# EFM32JG12B500F1024GL125 register map
File version: 4.0.0
CPU: CM3 r2p1, little endian, MPU, no FPU, 3 interrupt priority bits
Registers are 32-bit, read-write, reset 0x0 unless marked. A register's access mark holds for its fields unless they carry their own. Offsets are from the block's base; [hi:lo] are bit positions; lines under a group give offsets from that group; {n}, {i} and the like mark numbered series; 'fields as' and 'values as' point back to an identical list.

## GPIO
Base 0x4000A000
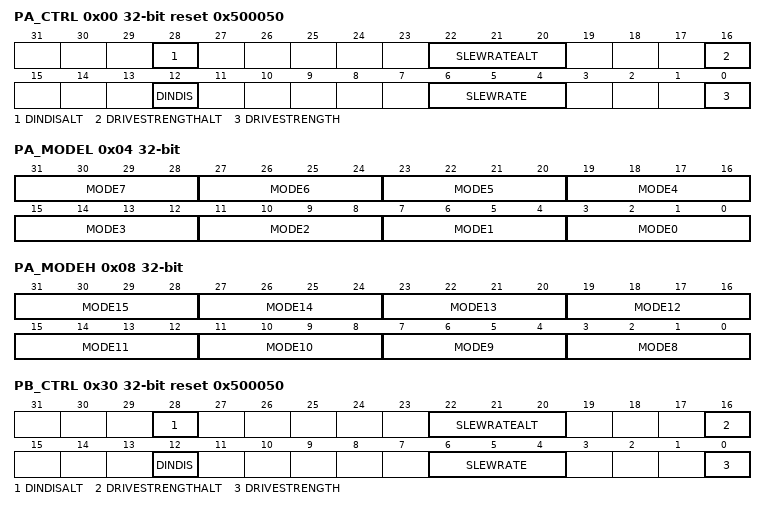
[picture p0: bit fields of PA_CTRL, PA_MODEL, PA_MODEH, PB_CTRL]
0x00 PA_CTRL reset 0x500050 — Port Control Register
  [28] DINDISALT — Alternate Data in Disable
  [22:20] SLEWRATEALT — Alternate Slewrate Limit for Port
  [16] DRIVESTRENGTHALT — Alternate Drive Strength for Port
  [12] DINDIS — Data in Disable
  [6:4] SLEWRATE — Slewrate Limit for Port
  [0] DRIVESTRENGTH — Drive Strength for Port
0x04 PA_MODEL — Port Pin Mode Low Register
  [all] fields
    0=DISABLED (Input disabled. Pullup if DOUT is set.); 1=INPUT (Input enabled. Filter if DOUT is set); 2=INPUTPULL (Input enabled. DOUT determines pull direction); 3=INPUTPULLFILTER (Input enabled with filter. DOUT determines pull direction); 4=PUSHPULL (Push-pull output); 5=PUSHPULLALT (Push-pull using alternate control); 6=WIREDOR (Wired-or output); 7=WIREDORPULLDOWN (Wired-or output with pull-down); 8=WIREDAND (Open-drain output); 9=WIREDANDFILTER (Open-drain output with filter); 10=WIREDANDPULLUP (Open-drain output with pullup); 11=WIREDANDPULLUPFILTER (Open-drain output with filter and pullup); 12=WIREDANDALT (Open-drain output using alternate control); 13=WIREDANDALTFILTER (Open-drain output using alternate control with filter); 14=WIREDANDALTPULLUP (Open-drain output using alternate control with pullup); 15=WIREDANDALTPULLUPFILTER (Open-drain output using alternate control with filter and pullup)
  [4n+3:4n] MODE{n} (n=0..7) — Pin {n} Mode
0x08 PA_MODEH — Port Pin Mode High Register
  [all] fields
    values as the fields of PA_MODEL
  [4n-29:4n-32] MODE{n} (n=8..15) — Pin {n} Mode
0x0C PA_DOUT — Port Data Out Register
  [15:0] DOUT — Data Out
0x18 PA_DOUTTGL wo — Port Data Out Toggle Register
  [15:0] DOUTTGL — Data Out Toggle
0x1C PA_DIN ro — Port Data in Register
  [15:0] DIN — Data in
0x20 PA_PINLOCKN reset 0xFFFF — Port Unlocked Pins Register
  [15:0] PINLOCKN — Unlocked Pins
0x28 PA_OVTDIS — Over Voltage Disable for All Modes
  [15:0] OVTDIS — Disable Over Voltage Capability
0x30 PB_CTRL reset 0x500050 — Port Control Register
  fields as PA_CTRL
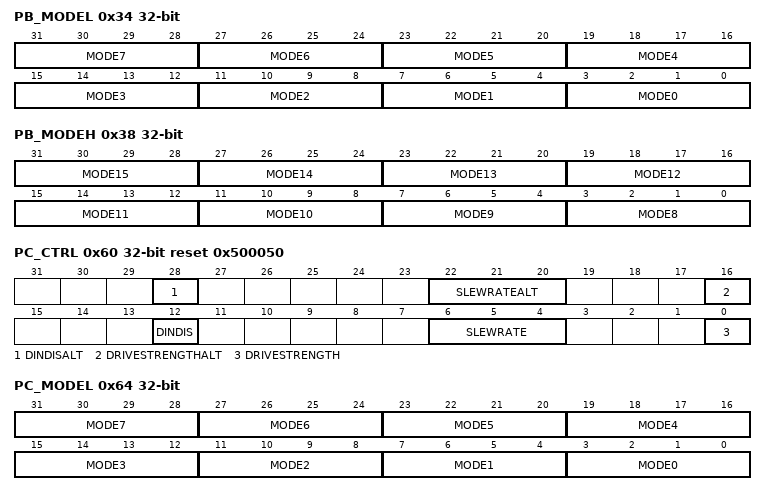
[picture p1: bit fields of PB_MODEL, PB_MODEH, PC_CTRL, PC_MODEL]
0x34 PB_MODEL — Port Pin Mode Low Register
  fields as PA_MODEL
0x38 PB_MODEH — Port Pin Mode High Register
  fields as PA_MODEH
0x3C PB_DOUT — Port Data Out Register
  [15:0] DOUT — Data Out
0x48 PB_DOUTTGL wo — Port Data Out Toggle Register
  [15:0] DOUTTGL — Data Out Toggle
0x4C PB_DIN ro — Port Data in Register
  [15:0] DIN — Data in
0x50 PB_PINLOCKN reset 0xFFFF — Port Unlocked Pins Register
  [15:0] PINLOCKN — Unlocked Pins
0x58 PB_OVTDIS — Over Voltage Disable for All Modes
  [15:0] OVTDIS — Disable Over Voltage Capability
0x60 PC_CTRL reset 0x500050 — Port Control Register
  fields as PA_CTRL
0x64 PC_MODEL — Port Pin Mode Low Register
  fields as PA_MODEL
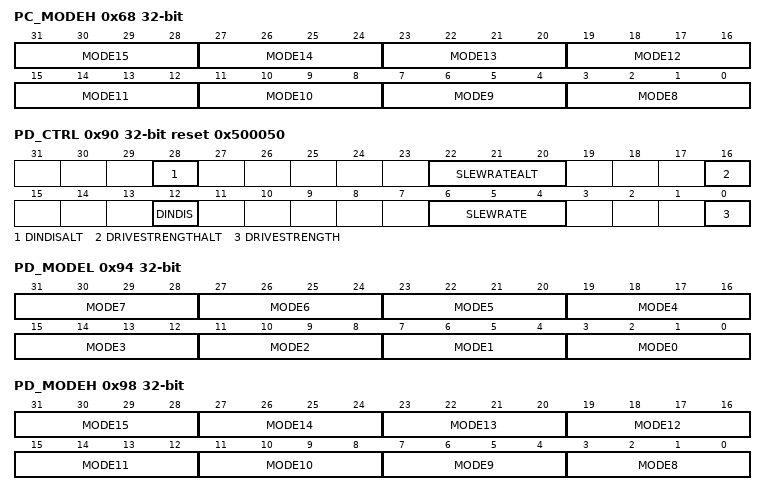
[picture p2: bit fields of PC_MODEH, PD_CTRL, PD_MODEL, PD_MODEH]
0x68 PC_MODEH — Port Pin Mode High Register
  fields as PA_MODEH
0x6C PC_DOUT — Port Data Out Register
  [15:0] DOUT — Data Out
0x78 PC_DOUTTGL wo — Port Data Out Toggle Register
  [15:0] DOUTTGL — Data Out Toggle
0x7C PC_DIN ro — Port Data in Register
  [15:0] DIN — Data in
0x80 PC_PINLOCKN reset 0xFFFF — Port Unlocked Pins Register
  [15:0] PINLOCKN — Unlocked Pins
0x88 PC_OVTDIS — Over Voltage Disable for All Modes
  [15:0] OVTDIS — Disable Over Voltage Capability
0x90 PD_CTRL reset 0x500050 — Port Control Register
  fields as PA_CTRL
0x94 PD_MODEL — Port Pin Mode Low Register
  fields as PA_MODEL
0x98 PD_MODEH — Port Pin Mode High Register
  fields as PA_MODEH
0x9C PD_DOUT — Port Data Out Register
  [15:0] DOUT — Data Out
0xA8 PD_DOUTTGL wo — Port Data Out Toggle Register
  [15:0] DOUTTGL — Data Out Toggle
0xAC PD_DIN ro — Port Data in Register
  [15:0] DIN — Data in
0xB0 PD_PINLOCKN reset 0xFFFF — Port Unlocked Pins Register
  [15:0] PINLOCKN — Unlocked Pins
0xB8 PD_OVTDIS — Over Voltage Disable for All Modes
  [15:0] OVTDIS — Disable Over Voltage Capability
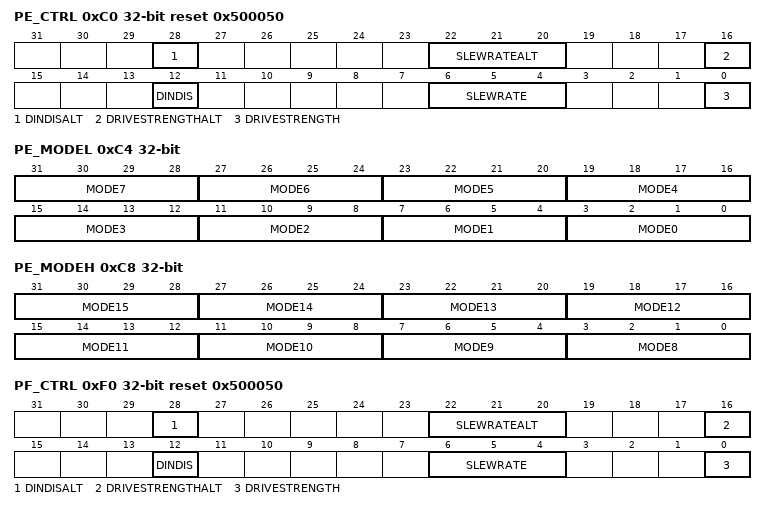
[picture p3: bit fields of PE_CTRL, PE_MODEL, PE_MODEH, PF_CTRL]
0xC0 PE_CTRL reset 0x500050 — Port Control Register
  fields as PA_CTRL
0xC4 PE_MODEL — Port Pin Mode Low Register
  fields as PA_MODEL
0xC8 PE_MODEH — Port Pin Mode High Register
  fields as PA_MODEH
0xCC PE_DOUT — Port Data Out Register
  [15:0] DOUT — Data Out
0xD8 PE_DOUTTGL wo — Port Data Out Toggle Register
  [15:0] DOUTTGL — Data Out Toggle
0xDC PE_DIN ro — Port Data in Register
  [15:0] DIN — Data in
0xE0 PE_PINLOCKN reset 0xFFFF — Port Unlocked Pins Register
  [15:0] PINLOCKN — Unlocked Pins
0xE8 PE_OVTDIS — Over Voltage Disable for All Modes
  [15:0] OVTDIS — Disable Over Voltage Capability
0xF0 PF_CTRL reset 0x500050 — Port Control Register
  fields as PA_CTRL
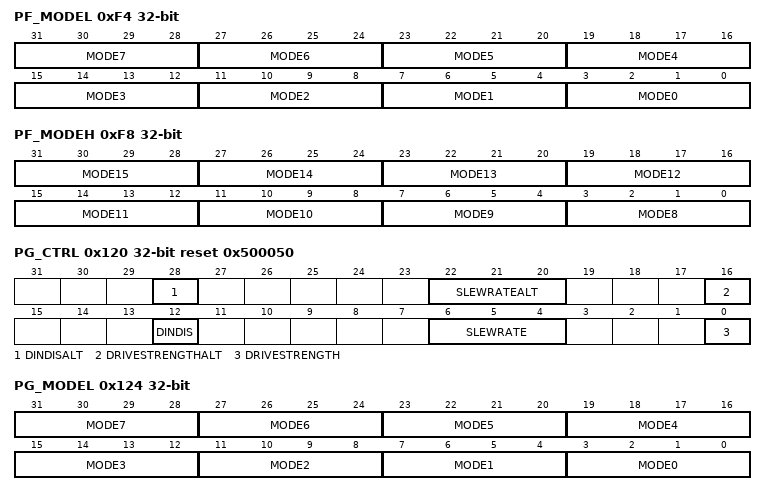
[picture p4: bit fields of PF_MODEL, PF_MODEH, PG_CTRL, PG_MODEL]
0xF4 PF_MODEL — Port Pin Mode Low Register
  fields as PA_MODEL
0xF8 PF_MODEH — Port Pin Mode High Register
  fields as PA_MODEH
0xFC PF_DOUT — Port Data Out Register
  [15:0] DOUT — Data Out
0x108 PF_DOUTTGL wo — Port Data Out Toggle Register
  [15:0] DOUTTGL — Data Out Toggle
0x10C PF_DIN ro — Port Data in Register
  [15:0] DIN — Data in
0x110 PF_PINLOCKN reset 0xFFFF — Port Unlocked Pins Register
  [15:0] PINLOCKN — Unlocked Pins
0x118 PF_OVTDIS — Over Voltage Disable for All Modes
  [15:0] OVTDIS — Disable Over Voltage Capability
0x120 PG_CTRL reset 0x500050 — Port Control Register
  fields as PA_CTRL
0x124 PG_MODEL — Port Pin Mode Low Register
  fields as PA_MODEL
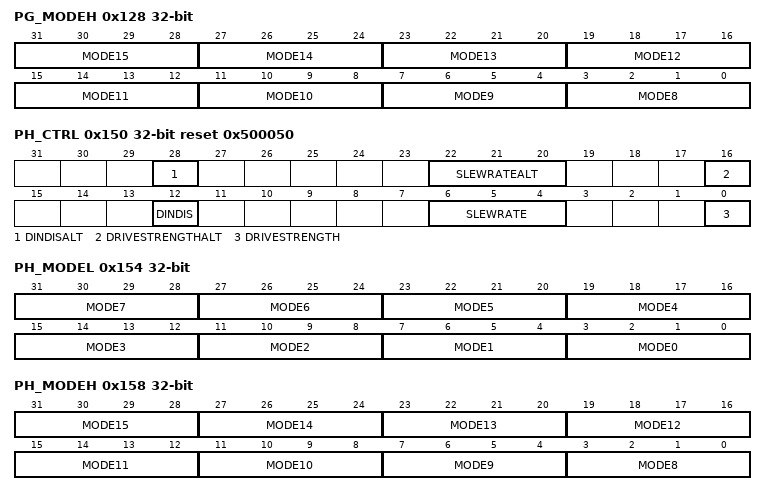
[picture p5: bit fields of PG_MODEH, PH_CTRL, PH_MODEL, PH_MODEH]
0x128 PG_MODEH — Port Pin Mode High Register
  fields as PA_MODEH
0x12C PG_DOUT — Port Data Out Register
  [15:0] DOUT — Data Out
0x138 PG_DOUTTGL wo — Port Data Out Toggle Register
  [15:0] DOUTTGL — Data Out Toggle
0x13C PG_DIN ro — Port Data in Register
  [15:0] DIN — Data in
0x140 PG_PINLOCKN reset 0xFFFF — Port Unlocked Pins Register
  [15:0] PINLOCKN — Unlocked Pins
0x148 PG_OVTDIS — Over Voltage Disable for All Modes
  [15:0] OVTDIS — Disable Over Voltage Capability
0x150 PH_CTRL reset 0x500050 — Port Control Register
  fields as PA_CTRL
0x154 PH_MODEL — Port Pin Mode Low Register
  fields as PA_MODEL
0x158 PH_MODEH — Port Pin Mode High Register
  fields as PA_MODEH
0x15C PH_DOUT — Port Data Out Register
  [15:0] DOUT — Data Out
0x168 PH_DOUTTGL wo — Port Data Out Toggle Register
  [15:0] DOUTTGL — Data Out Toggle
0x16C PH_DIN ro — Port Data in Register
  [15:0] DIN — Data in
0x170 PH_PINLOCKN reset 0xFFFF — Port Unlocked Pins Register
  [15:0] PINLOCKN — Unlocked Pins
0x178 PH_OVTDIS — Over Voltage Disable for All Modes
  [15:0] OVTDIS — Disable Over Voltage Capability
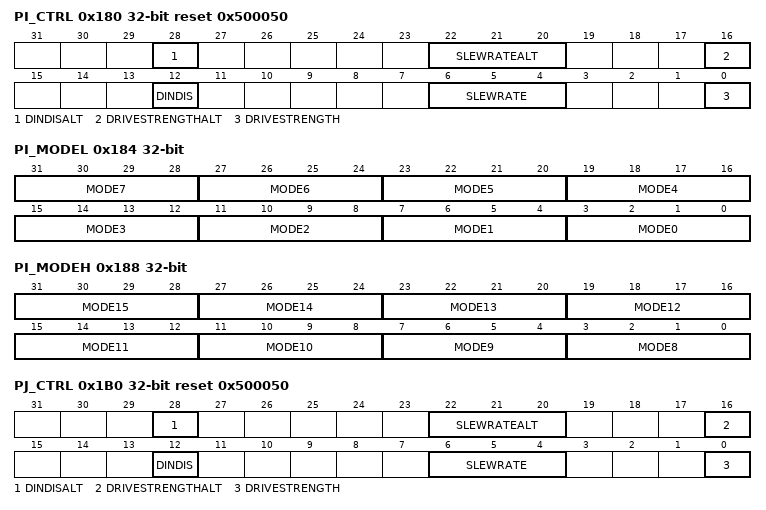
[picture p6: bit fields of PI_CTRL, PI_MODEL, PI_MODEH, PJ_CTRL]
0x180 PI_CTRL reset 0x500050 — Port Control Register
  fields as PA_CTRL
0x184 PI_MODEL — Port Pin Mode Low Register
  fields as PA_MODEL
0x188 PI_MODEH — Port Pin Mode High Register
  fields as PA_MODEH
0x18C PI_DOUT — Port Data Out Register
  [15:0] DOUT — Data Out
0x198 PI_DOUTTGL wo — Port Data Out Toggle Register
  [15:0] DOUTTGL — Data Out Toggle
0x19C PI_DIN ro — Port Data in Register
  [15:0] DIN — Data in
0x1A0 PI_PINLOCKN reset 0xFFFF — Port Unlocked Pins Register
  [15:0] PINLOCKN — Unlocked Pins
0x1A8 PI_OVTDIS — Over Voltage Disable for All Modes
  [15:0] OVTDIS — Disable Over Voltage Capability
0x1B0 PJ_CTRL reset 0x500050 — Port Control Register
  fields as PA_CTRL
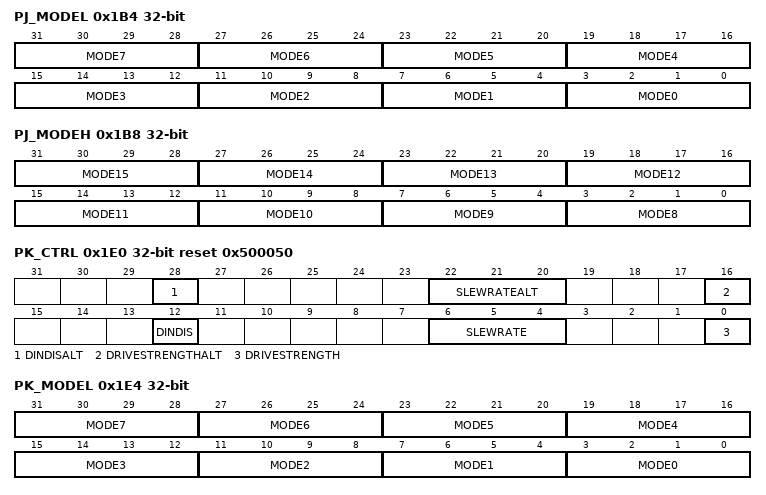
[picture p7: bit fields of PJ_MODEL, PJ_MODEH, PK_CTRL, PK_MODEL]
0x1B4 PJ_MODEL — Port Pin Mode Low Register
  fields as PA_MODEL
0x1B8 PJ_MODEH — Port Pin Mode High Register
  fields as PA_MODEH
0x1BC PJ_DOUT — Port Data Out Register
  [15:0] DOUT — Data Out
0x1C8 PJ_DOUTTGL wo — Port Data Out Toggle Register
  [15:0] DOUTTGL — Data Out Toggle
0x1CC PJ_DIN ro — Port Data in Register
  [15:0] DIN — Data in
0x1D0 PJ_PINLOCKN reset 0xFFFF — Port Unlocked Pins Register
  [15:0] PINLOCKN — Unlocked Pins
0x1D8 PJ_OVTDIS — Over Voltage Disable for All Modes
  [15:0] OVTDIS — Disable Over Voltage Capability
0x1E0 PK_CTRL reset 0x500050 — Port Control Register
  fields as PA_CTRL
0x1E4 PK_MODEL — Port Pin Mode Low Register
  fields as PA_MODEL
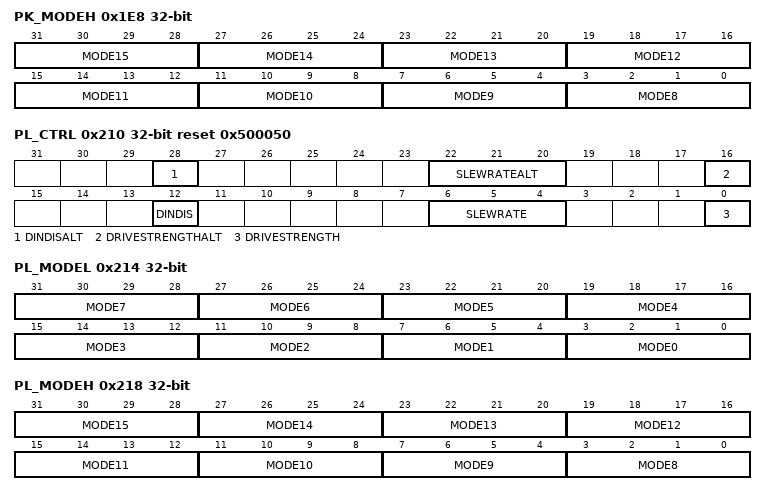
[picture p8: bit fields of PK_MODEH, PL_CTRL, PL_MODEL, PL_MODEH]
0x1E8 PK_MODEH — Port Pin Mode High Register
  fields as PA_MODEH
0x1EC PK_DOUT — Port Data Out Register
  [15:0] DOUT — Data Out
0x1F8 PK_DOUTTGL wo — Port Data Out Toggle Register
  [15:0] DOUTTGL — Data Out Toggle
0x1FC PK_DIN ro — Port Data in Register
  [15:0] DIN — Data in
0x200 PK_PINLOCKN reset 0xFFFF — Port Unlocked Pins Register
  [15:0] PINLOCKN — Unlocked Pins
0x208 PK_OVTDIS — Over Voltage Disable for All Modes
  [15:0] OVTDIS — Disable Over Voltage Capability
0x210 PL_CTRL reset 0x500050 — Port Control Register
  fields as PA_CTRL
0x214 PL_MODEL — Port Pin Mode Low Register
  fields as PA_MODEL
0x218 PL_MODEH — Port Pin Mode High Register
  fields as PA_MODEH
0x21C PL_DOUT — Port Data Out Register
  [15:0] DOUT — Data Out
0x228 PL_DOUTTGL wo — Port Data Out Toggle Register
  [15:0] DOUTTGL — Data Out Toggle
0x22C PL_DIN ro — Port Data in Register
  [15:0] DIN — Data in
0x230 PL_PINLOCKN reset 0xFFFF — Port Unlocked Pins Register
  [15:0] PINLOCKN — Unlocked Pins
0x238 PL_OVTDIS — Over Voltage Disable for All Modes
  [15:0] OVTDIS — Disable Over Voltage Capability
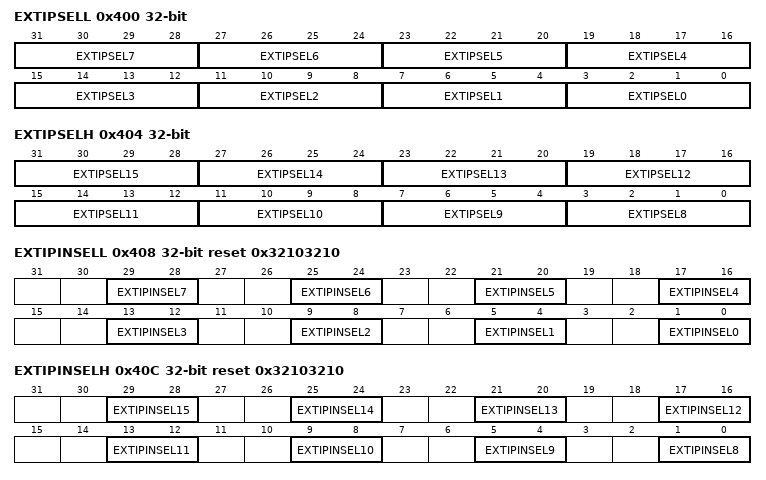
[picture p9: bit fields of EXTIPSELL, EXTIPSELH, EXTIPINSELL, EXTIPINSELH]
0x400 EXTIPSELL — External Interrupt Port Select Low Register
  [4n+3:4n] EXTIPSEL{n} (n=0..7) — External Interrupt {n} Port Select
    0=PORTA (Port A group selected for external interrupt {n}); 1=PORTB (Port B group selected for external interrupt {n}); 2=PORTC (Port C group selected for external interrupt {n}); 3=PORTD (Port D group selected for external interrupt {n}); 5=PORTF (Port F group selected for external interrupt {n}); 8=PORTI (Port I group selected for external interrupt {n}); 9=PORTJ (Port J group selected for external interrupt {n}); 10=PORTK (Port K group selected for external interrupt {n})
0x404 EXTIPSELH — External Interrupt Port Select High Register
  [4n-29:4n-32] EXTIPSEL{n} (n=8..15) — External Interrupt {n} Port Select
    values as EXTIPSELL.EXTIPSEL0
0x408 EXTIPINSELL reset 0x32103210 — External Interrupt Pin Select Low Register
  [4n+1:4n] EXTIPINSEL{n} (n=4..7) — External Interrupt {n} Pin Select
    {v}=PIN{v+4} (v=0..3)
  [4n+1:4n] EXTIPINSEL{n} (n=0..3) — External Interrupt {n} Pin Select
    {v}=PIN{v} (v=0..3)
0x40C EXTIPINSELH reset 0x32103210 — External Interrupt Pin Select High Register
  [4n-31:4n-32] EXTIPINSEL{n} (n=12..15) — External Interrupt {n} Pin Select
    {v}=PIN{v+12} (v=0..3)
  [4n-31:4n-32] EXTIPINSEL{n} (n=8..11) — External Interrupt {n} Pin Select
    {v}=PIN{v+8} (v=0..3)
0x410 EXTIRISE — External Interrupt Rising Edge Trigger Register
  [15:0] EXTIRISE — External Interrupt N Rising Edge Trigger Enable
0x414 EXTIFALL — External Interrupt Falling Edge Trigger Register
  [15:0] EXTIFALL — External Interrupt N Falling Edge Trigger Enable
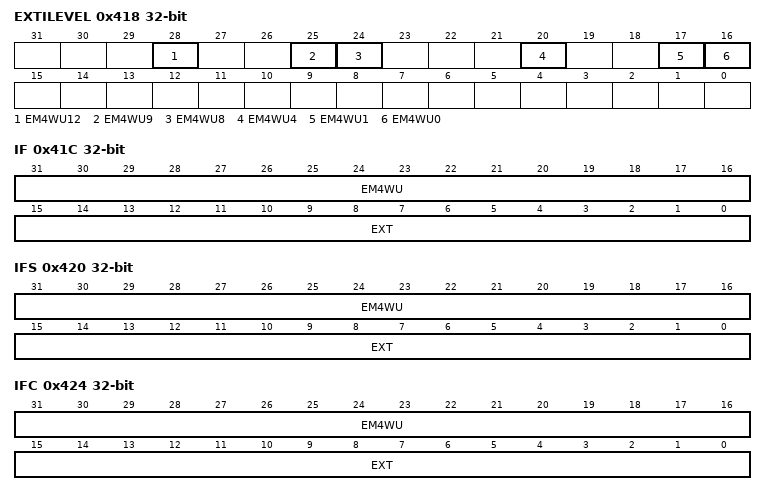
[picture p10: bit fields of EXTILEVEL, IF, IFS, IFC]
0x418 EXTILEVEL — External Interrupt Level Register
  [28] EM4WU12 — EM4 Wake Up Level for EM4WU12 Pin
  [25] EM4WU9 — EM4 Wake Up Level for EM4WU9 Pin
  [24] EM4WU8 — EM4 Wake Up Level for EM4WU8 Pin
  [20] EM4WU4 — EM4 Wake Up Level for EM4WU4 Pin
  [17] EM4WU1 — EM4 Wake Up Level for EM4WU1 Pin
  [16] EM4WU0 — EM4 Wake Up Level for EM4WU0 Pin
0x41C IF ro — Interrupt Flag Register
  [31:16] EM4WU — EM4 Wake Up Pin Interrupt Flag
  [15:0] EXT — External Pin Interrupt Flag
0x420 IFS wo — Interrupt Flag Set Register
  [31:16] EM4WU — Set EM4WU Interrupt Flag
  [15:0] EXT — Set EXT Interrupt Flag
0x424 IFC wo — Interrupt Flag Clear Register
  [31:16] EM4WU — Clear EM4WU Interrupt Flag
  [15:0] EXT — Clear EXT Interrupt Flag
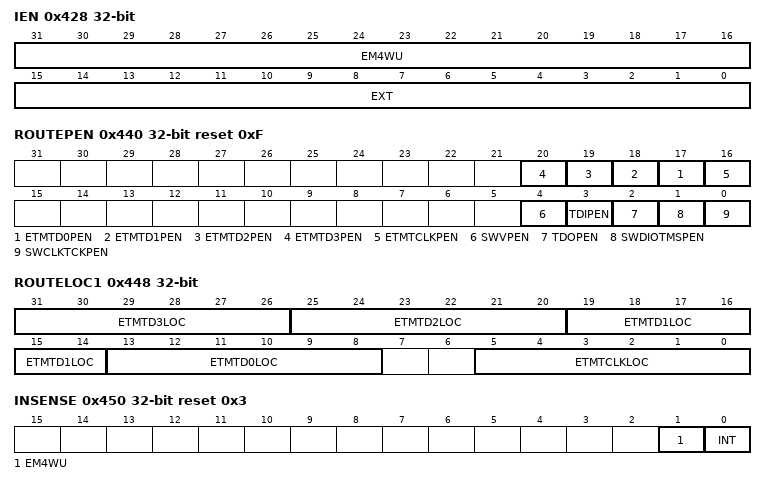
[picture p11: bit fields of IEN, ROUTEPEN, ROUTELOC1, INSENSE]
0x428 IEN — Interrupt Enable Register
  [31:16] EM4WU — EM4WU Interrupt Enable
  [15:0] EXT — EXT Interrupt Enable
0x42C EM4WUEN — EM4 Wake Up Enable Register
  [31:16] EM4WUEN — EM4 Wake Up Enable
0x440 ROUTEPEN reset 0xF — I/O Routing Pin Enable Register
  [n+17] ETMTD{n}PEN (n=0..3) — ETM Trace Data Pin Enable
  [16] ETMTCLKPEN — ETM Trace Clock Pin Enable
  [4] SWVPEN — Serial Wire Viewer Output Pin Enable
  [3] TDIPEN — JTAG Test Debug Input Pin Enable
  [2] TDOPEN — JTAG Test Debug Output Pin Enable
  [1] SWDIOTMSPEN — Serial Wire Data and JTAG Test Mode Select Pin Enable
  [0] SWCLKTCKPEN — Serial Wire Clock and JTAG Test Clock Pin Enable
0x444 ROUTELOC0 — I/O Routing Location Register
  [5:0] SWVLOC — I/O Location
    {v}=LOC{v} (Location {v}) (v=0..3)
0x448 ROUTELOC1 — I/O Routing Location Register 1
  [all] fields
    {v}=LOC{v} (Location {v}) (v=0..3)
  [6n+13:6n+8] ETMTD{n}LOC (n=0..3) — I/O Location
  [5:0] ETMTCLKLOC — I/O Location
0x450 INSENSE reset 0x3 — Input Sense Register
  [1] EM4WU — EM4WU Interrupt Sense Enable
  [0] INT — Interrupt Sense Enable
0x454 LOCK — Configuration Lock Register
  [15:0] LOCKKEY — Configuration Lock Key
    0=UNLOCKED; 1=LOCKED

## Notices in the file
# License
Copyright 2021 Silicon Laboratories Inc. www.silabs.com
SPDX-License-Identifier: Zlib
The licensor of this software is Silicon Laboratories Inc.
This software is provided 'as-is', without any express or implied
warranty. In no event will the authors be held liable for any damages
arising from the use of this software.
Permission is granted to anyone to use this software for any purpose,
including commercial applications, and to alter it and redistribute it
freely, subject to the following restrictions:
1. The origin of this software must not be misrepresented; you must not
claim that you wrote the original software. If you use this software
in a product, an acknowledgment in the product documentation would be
appreciated but is not required.
2. Altered source versions must be plainly marked as such, and must not be
misrepresented as being the original software.
3. This notice may not be removed or altered from any source distribution.
